VERSION ""

NS_ :

BS_:

BU_: CMC_UNIT

BO_ 100 HANDSHAKE: 16 CMC_UNIT
 SG_ hw_version_major : 0|8@1+ (1,0) [0|255] ""  CMC_UNIT
 SG_ hw_version_minor : 8|8@1+ (1,0) [0|255] ""  CMC_UNIT
 SG_ unit_id : 16|8@1+ (1,0) [0|255] ""  CMC_UNIT
 SG_ unit_type : 24|8@1+ (1,0) [0|255] ""  CMC_UNIT
 SG_ fw_version_major : 32|8@1+ (1,0) [0|255] ""  CMC_UNIT
 SG_ fw_version_minor : 40|8@1+ (1,0) [0|255] ""  CMC_UNIT
 SG_ gc_datetime : 48|32@1+ (1,0) [0|4294967295] ""  CMC_UNIT
 SG_ gc_hash : 80|32@1+ (1,0) [0|4294967295] ""  CMC_UNIT

BO_ 101 HEARTBEAT: 1 CMC_UNIT
 SG_ unit_id : 0|6@1+ (1,0) [0|63] ""  CMC_UNIT
 SG_ system_state : 6|2@1+ (1,0) [0|3] ""  CMC_UNIT

BO_ 202 FEATURE_HORN: 1 CMC_UNIT
 SG_ horn_on : 0|1@1+ (1,0) [0|1] "" Vector__XXX

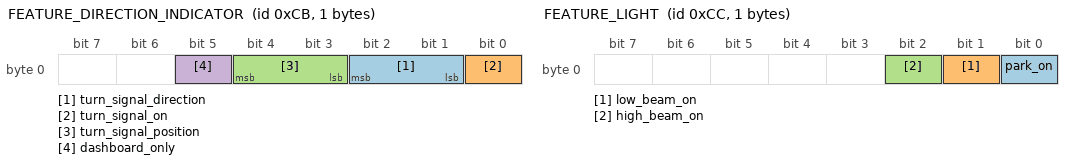
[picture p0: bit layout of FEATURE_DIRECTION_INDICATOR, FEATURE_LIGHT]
BO_ 203 FEATURE_DIRECTION_INDICATOR: 1 CMC_UNIT
 SG_ turn_signal_direction : 1|2@1+ (1,0) [0|2] "" Vector__XXX
 SG_ turn_signal_on : 0|1@1+ (1,0) [0|1] "" Vector__XXX
 SG_ turn_signal_position : 3|2@1+ (1,0) [0|2] "" Vector__XXX
 SG_ dashboard_only : 5|1@1+ (1,0) [0|1] "" Vector__XXX

BO_ 200 FEATURE_IGNITION: 1 CMC_UNIT
 SG_ ignition_on : 0|1@1+ (1,0) [0|1] "" Vector__XXX

BO_ 201 FEATURE_STARTER: 1 CMC_UNIT
 SG_ starter_on : 0|1@1+ (1,0) [0|1] "" Vector__XXX

BO_ 204 FEATURE_LIGHT: 1 CMC_UNIT
 SG_ park_on : 0|1@1+ (1,0) [0|1] "" Vector__XXX
 SG_ low_beam_on : 1|1@1+ (1,0) [0|1] "" Vector__XXX
 SG_ high_beam_on : 2|1@1+ (1,0) [0|1] "" Vector__XXX

BO_ 3221225472 VECTOR__INDEPENDENT_SIG_MSG: 0 Vector__XXX
 SG_ NewSignal_0004 : 24|8@1+ (1,0) [0|0] "" Vector__XXX

BO_ 205 FEATURE_BRAKE_LIGHT: 1 CMC_UNIT
 SG_ brake_light_on : 0|1@1+ (1,0) [0|1] "" Vector__XXX

BO_ 206 FEATURE_NEUTRAL_SENSOR: 1 CMC_UNIT
 SG_ neutral_engaged : 0|1@1+ (1,0) [0|1] "" Vector__XXX

BO_ 207 FEATURE_OIL_PRESSURE_SENSOR: 1 CMC_UNIT
 SG_ oil_pressure_low_detected : 0|1@1+ (1,0) [0|1] "" Vector__XXX

CM_ BO_ 100 "Startup init to check ID and FW for all units, inititate reset or reconfig if needed";
CM_ SG_ 100 hw_version_major "Hardware major version";
CM_ SG_ 100 hw_version_minor "Hardware minor version";
CM_ SG_ 100 unit_id "Unique ID for the source unit";
CM_ SG_ 100 unit_type "Unit type";
CM_ SG_ 100 fw_version_major "Firmware major version, should listed for compability to ensure units can be combined";
CM_ SG_ 100 fw_version_minor "Firmware minor version, for info only";
CM_ SG_ 100 gc_datetime "All global configs across all units must be the same, datetime is when the config was created/updated, if not the same across units or if missing, the most recent updated config is to be used and passed over to units with old config";
CM_ SG_ 100 gc_hash "All global configs across all units must be the same, this hash represent global config checksum";
CM_ BO_ 101 "Poll on system frequently to identify missing units or mishaps";
CM_ SG_ 101 unit_id "Unique ID for the source unit";
CM_ SG_ 101 system_state "Report system state for taking action if not OK";
CM_ BO_ 202 "Turn horn on/off";
CM_ SG_ 202 horn_on "0=off, 1=on";
CM_ BO_ 203 "Turn direction indicators on/off, send also info for left, righ or both (hazard) and optionally if to be turned of only for front or rear, normally should be both. Separate for turning on indicator only, to be used for startup animation or check that dashboard indicator bulb works";
CM_ SG_ 203 turn_signal_direction "0=left, 1=right, 2=both";
CM_ SG_ 203 turn_signal_on "0=off, 1=on";
CM_ SG_ 203 turn_signal_position "0=front, 1=rear, 2=both";
CM_ SG_ 203 dashboard_only "0=normal operation, 1=only affect dashboard warning indicator";
CM_ BO_ 200 "Control ignition status";
CM_ SG_ 200 ignition_on "0=off, 1=on";
CM_ BO_ 201 "Control starter motor";
CM_ SG_ 201 starter_on "0=off, 1=engaged (on)";
CM_ BO_ 204 "Lights: park, low beam and high beam";
CM_ SG_ 204 park_on "0 = off, 1=on";
CM_ SG_ 204 low_beam_on "0 = off, 1=on";
CM_ SG_ 204 high_beam_on "0 = off, 1=on";
CM_ BO_ 205 "Lights: Brake Light";
CM_ SG_ 205 brake_light_on "0 = off, 1 = on";
CM_ BO_ 206 "Neutral sensor should activate dashboard light";
CM_ SG_ 206 neutral_engaged "0 = off, 1 = on";
CM_ BO_ 207 "Oil Pressure Sensor should activate warning light on dash";
CM_ SG_ 207 oil_pressure_low_detected "0 = normal operation, 1 = low pressure detected";
BA_DEF_  "BusType" STRING ;
BA_DEF_ BO_  "CANFD_BRS" ENUM  "0","1";
BA_DEF_ BO_  "VFrameFormat" ENUM  "StandardCAN","ExtendedCAN","reserved","reserved","reserved","reserved","reserved","reserved","reserved","reserved","reserved","reserved","reserved","reserved","StandardCAN_FD","ExtendedCAN_FD";
BA_DEF_DEF_  "BusType" "";
BA_DEF_DEF_  "CANFD_BRS" "0";
BA_DEF_DEF_  "VFrameFormat" "StandardCAN";
BA_ "BusType" "CAN FD";
BA_ "VFrameFormat" BO_ 100 14;
BA_ "CANFD_BRS" BO_ 100 1;
VAL_ 100 unit_type 0 "UNKNOWN" 1 "I/O UNIT" ;
VAL_ 101 system_state 0 "UNKNOWN" 1 "OK" 2 "WARNING" 3 "FAULT" ;
